# STM32F051xx register map
File version: 1.0
Registers are 32-bit, read-write, reset 0x0 unless marked. A register's access mark holds for its fields unless they carry their own. Offsets are from the block's base; [hi:lo] are bit positions; {n}, {i} and the like mark numbered series.

## IWDG — Independent watchdog
Base 0x40003000
0x00 KR wo — Key register
  [15:0] KEY — Key value
0x04 PR — Prescaler register
  [2:0] PR — Prescaler divider
0x08 RLR reset 0xFFF — Reload register
  [11:0] RL — Watchdog counter reload value
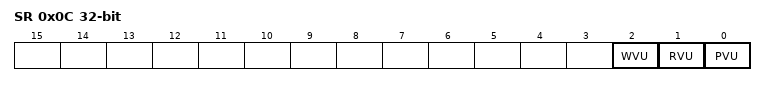
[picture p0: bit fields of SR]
0x0C SR ro — Status register
  [2] WVU — Watchdog counter window value update
  [1] RVU — Watchdog counter reload value update
  [0] PVU — Watchdog prescaler value update
0x10 WINR reset 0xFFF — Window register
  [11:0] WIN — Watchdog counter window value

## WWDG — Window watchdog
Base 0x40002C00
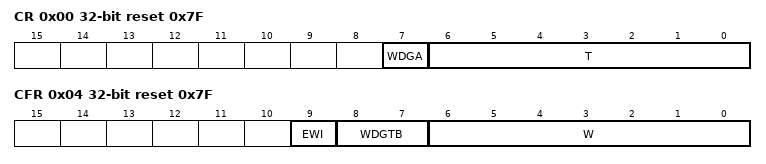
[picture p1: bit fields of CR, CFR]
0x00 CR reset 0x7F — Control register
  [7] WDGA — Activation bit
  [6:0] T — 7-bit counter
0x04 CFR reset 0x7F — Configuration register
  [9] EWI — Early wakeup interrupt
  [8:7] WDGTB — Timer base
  [6:0] W — 7-bit window value
0x08 SR — Status register
  [0] EWIF — Early wakeup interrupt flag

## TIM14 — General-purpose-timers
Base 0x40002000
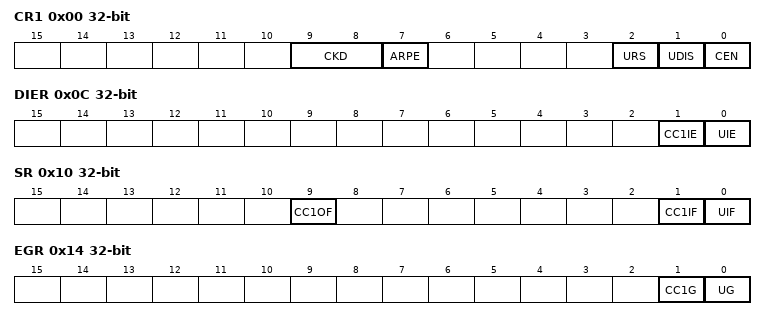
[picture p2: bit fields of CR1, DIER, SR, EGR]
0x00 CR1 — control register 1
  [9:8] CKD — Clock division
  [7] ARPE — Auto-reload preload enable
  [2] URS — Update request source
  [1] UDIS — Update disable
  [0] CEN — Counter enable
0x0C DIER — DMA/Interrupt enable register
  [1] CC1IE — Capture/Compare 1 interrupt enable
  [0] UIE — Update interrupt enable
0x10 SR — status register
  [9] CC1OF — Capture/Compare 1 overcapture flag
  [1] CC1IF — Capture/compare 1 interrupt flag
  [0] UIF — Update interrupt flag
0x14 EGR wo — event generation register
  [1] CC1G — Capture/compare 1 generation
  [0] UG — Update generation
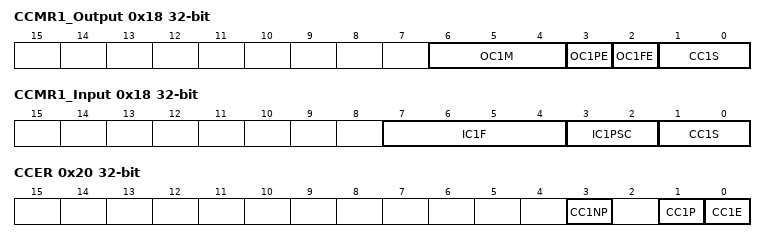
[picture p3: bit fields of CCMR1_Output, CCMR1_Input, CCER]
0x18 CCMR1_Output — capture/compare mode register (output mode)
  [6:4] OC1M — Output Compare 1 mode
  [3] OC1PE — Output Compare 1 preload enable
  [2] OC1FE — Output compare 1 fast enable
  [1:0] CC1S — Capture/Compare 1 selection
0x18 CCMR1_Input (alternate view of CCMR1_Output) — capture/compare mode register (input mode)
  [7:4] IC1F — Input capture 1 filter
  [3:2] IC1PSC — Input capture 1 prescaler
  [1:0] CC1S — Capture/Compare 1 selection
0x20 CCER — capture/compare enable register
  [3] CC1NP — Capture/Compare 1 output Polarity
  [1] CC1P — Capture/Compare 1 output Polarity
  [0] CC1E — Capture/Compare 1 output enable
0x24 CNT — counter
  [15:0] CNT — counter value
0x28 PSC — prescaler
  [15:0] PSC — Prescaler value
0x2C ARR — auto-reload register
  [15:0] ARR — Auto-reload value
0x34 CCR1 — capture/compare register 1
  [15:0] CCR1 — Capture/Compare 1 value
0x50 OR — option register
  [1:0] RMP — Timer input 1 remap

## TIM6 — Basic-timers
Base 0x40001000
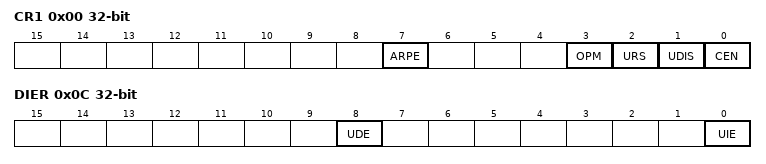
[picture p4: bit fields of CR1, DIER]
0x00 CR1 — control register 1
  [7] ARPE — Auto-reload preload enable
  [3] OPM — One-pulse mode
  [2] URS — Update request source
  [1] UDIS — Update disable
  [0] CEN — Counter enable
0x04 CR2 — control register 2
  [6:4] MMS — Master mode selection
0x0C DIER — DMA/Interrupt enable register
  [8] UDE — Update DMA request enable
  [0] UIE — Update interrupt enable
0x10 SR — status register
  [0] UIF — Update interrupt flag
0x14 EGR wo — event generation register
  [0] UG — Update generation
0x24 CNT — counter
  [15:0] CNT — Low counter value
0x28 PSC — prescaler
  [15:0] PSC — Prescaler value
0x2C ARR — auto-reload register
  [15:0] ARR — Low Auto-reload value

## EXTI — External interrupt/event controller
Base 0x40010400
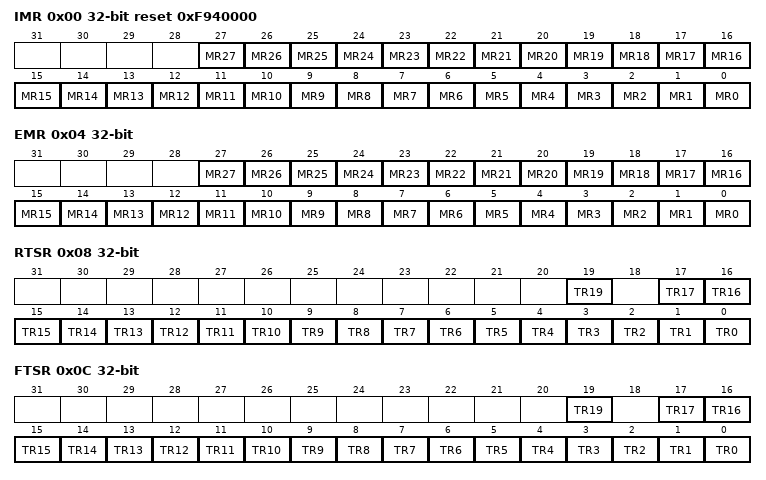
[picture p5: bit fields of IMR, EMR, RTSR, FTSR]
0x00 IMR reset 0xF940000 — Interrupt mask register (EXTI_IMR)
  [n] MR{n} (n=0..27) — Interrupt Mask on line {n}
0x04 EMR — Event mask register (EXTI_EMR)
  [n] MR{n} (n=0..27) — Event Mask on line {n}
0x08 RTSR — Rising Trigger selection register (EXTI_RTSR)
  [19] TR19 — Rising trigger event configuration of line 19
  [n] TR{n} (n=0..17) — Rising trigger event configuration of line {n}
0x0C FTSR — Falling Trigger selection register (EXTI_FTSR)
  [19] TR19 — Falling trigger event configuration of line 19
  [n] TR{n} (n=0..17) — Falling trigger event configuration of line {n}
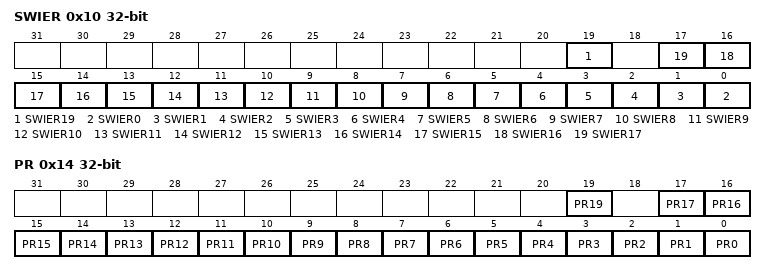
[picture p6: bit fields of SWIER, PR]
0x10 SWIER — Software interrupt event register (EXTI_SWIER)
  [19] SWIER19 — Software Interrupt on line 19
  [n] SWIER{n} (n=0..17) — Software Interrupt on line {n}
0x14 PR — Pending register (EXTI_PR)
  [19] PR19 — Pending bit 19
  [n] PR{n} (n=0..17) — Pending bit {n}
